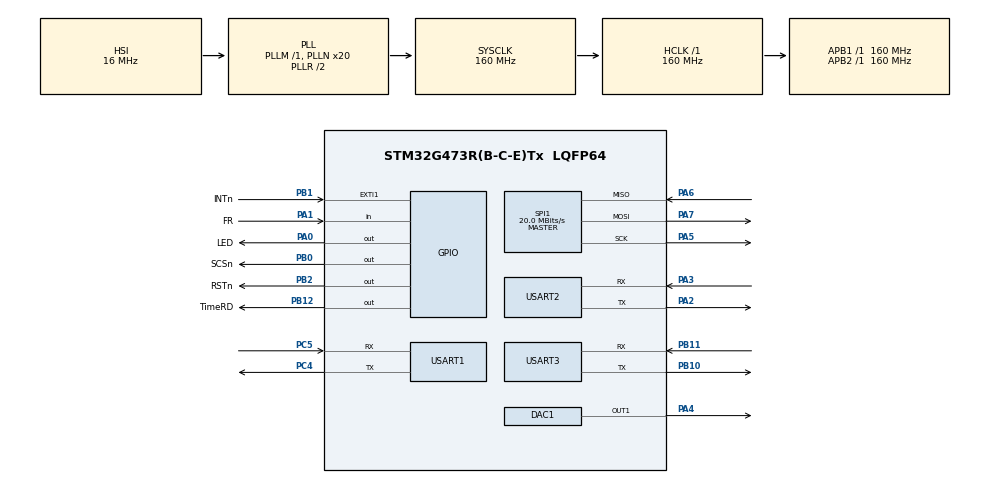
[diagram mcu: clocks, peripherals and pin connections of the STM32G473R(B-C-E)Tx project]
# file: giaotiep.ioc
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DAC1.DAC_Trigger_OUT1-DAC_OUT1=DAC_TRIGGER_T2_TRGO
Dma.DAC1_CH1.0.Direction=DMA_MEMORY_TO_PERIPH
Dma.DAC1_CH1.0.EventEnable=DISABLE
Dma.DAC1_CH1.0.Instance=DMA1_Channel1
Dma.DAC1_CH1.0.MemDataAlignment=DMA_MDATAALIGN_WORD
Dma.DAC1_CH1.0.MemInc=DMA_MINC_ENABLE
Dma.DAC1_CH1.0.Mode=DMA_CIRCULAR
Dma.DAC1_CH1.0.PeriphDataAlignment=DMA_PDATAALIGN_WORD
Dma.DAC1_CH1.0.PeriphInc=DMA_PINC_DISABLE
Dma.DAC1_CH1.0.Polarity=HAL_DMAMUX_REQ_GEN_RISING
Dma.DAC1_CH1.0.Priority=DMA_PRIORITY_HIGH
Dma.DAC1_CH1.0.RequestNumber=1
Dma.DAC1_CH1.0.SignalID=NONE
Dma.DAC1_CH1.0.SyncEnable=DISABLE
Dma.DAC1_CH1.0.SyncPolarity=HAL_DMAMUX_SYNC_NO_EVENT
Dma.DAC1_CH1.0.SyncRequestNumber=1
Dma.DAC1_CH1.0.SyncSignalID=NONE
Dma.Request0=DAC1_CH1
Mcu.Family=STM32G4
Mcu.Name=STM32G473R(B-C-E)Tx
Mcu.Package=LQFP64
NVIC.DMA1_Channel1_IRQn=true\:0\:0\:false\:false\:true\:false\:true\:true
NVIC.EXTI1_IRQn=true\:0\:0\:false\:false\:true\:true\:true\:true
NVIC.PriorityGroup=NVIC_PRIORITYGROUP_4
NVIC.TIM1_UP_TIM16_IRQn=true\:0\:0\:false\:false\:true\:true\:true\:true
NVIC.TIM20_UP_IRQn=true\:0\:0\:false\:false\:true\:true\:true\:true
NVIC.TIM3_IRQn=true\:0\:0\:false\:false\:true\:true\:true\:true
NVIC.USART1_IRQn=true\:0\:0\:false\:false\:true\:true\:true\:true
PA0.GPIO_Label=LED
PA0.Signal=GPIO_Output
PA1.GPIO_Label=FR
PA1.Signal=GPIO_Input
PA13.Mode=Serial_Wire
PA13.Signal=SYS_JTMS-SWDIO
PA14.Mode=Serial_Wire
PA14.Signal=SYS_JTCK-SWCLK
PA2.Mode=Asynchronous
PA2.Signal=USART2_TX
PA3.Mode=Asynchronous
PA3.Signal=USART2_RX
PA4.Signal=COMP_DAC11_group
PA5.Mode=Full_Duplex_Master
PA5.Signal=SPI1_SCK
PA6.Mode=Full_Duplex_Master
PA6.Signal=SPI1_MISO
PA7.Mode=Full_Duplex_Master
PA7.Signal=SPI1_MOSI
PB0.GPIO_Label=SCSn
PB0.Signal=GPIO_Output
PB1.GPIO_Label=INTn
PB1.GPIO_ModeDefaultEXTI=GPIO_MODE_IT_FALLING
PB1.GPIO_PuPd=GPIO_PULLUP
PB1.Signal=GPXTI1
PB10.Mode=Asynchronous
PB10.Signal=USART3_TX
PB11.Mode=Asynchronous
PB11.Signal=USART3_RX
PB12.GPIO_Label=TimeRD
PB12.Signal=GPIO_Output
PB2.GPIO_Label=RSTn
PB2.Signal=GPIO_Output
PC4.Mode=Asynchronous
PC4.Signal=USART1_TX
PC5.Mode=Asynchronous
PC5.Signal=USART1_RX
PF0-OSC_IN.Mode=HSE-External-Oscillator
PF0-OSC_IN.Signal=RCC_OSC_IN
PF1-OSC_OUT.Mode=HSE-External-Oscillator
PF1-OSC_OUT.Signal=RCC_OSC_OUT
ProjectManager.HeapSize=0x200
ProjectManager.StackSize=0x400
ProjectManager.TargetToolchain=MDK-ARM V5
RCC.ADC12Freq_Value=160000000
RCC.ADC345Freq_Value=160000000
RCC.AHBFreq_Value=160000000
RCC.APB1Freq_Value=160000000
RCC.APB1TimFreq_Value=160000000
RCC.APB2Freq_Value=160000000
RCC.APB2TimFreq_Value=160000000
RCC.CortexFreq_Value=160000000
RCC.EXTERNAL_CLOCK_VALUE=12288000
RCC.HCLKFreq_Value=160000000
RCC.HSE_VALUE=8000000
RCC.HSI48_VALUE=48000000
RCC.HSI_VALUE=16000000
RCC.LSE_VALUE=32768
RCC.PLLN=20
RCC.SYSCLKFreq_VALUE=160000000
RCC.SYSCLKSource=RCC_SYSCLKSOURCE_PLLCLK
RCC.USBFreq_Value=160000000
RCC.VCOOutputFreq_Value=320000000
SH.COMP_DAC11_group.0=DAC1_OUT1,DAC_OUT1
SPI1.BaudRatePrescaler=SPI_BAUDRATEPRESCALER_8
SPI1.CLKPhase=SPI_PHASE_2EDGE
SPI1.CLKPolarity=SPI_POLARITY_HIGH
SPI1.CRCCalculation=SPI_CRCCALCULATION_DISABLE
SPI1.CalculateBaudRate=20.0 MBits/s
SPI1.DataSize=SPI_DATASIZE_8BIT
SPI1.Direction=SPI_DIRECTION_2LINES
SPI1.Mode=SPI_MODE_MASTER
SPI1.VirtualType=VM_MASTER
TIM1.AutoReloadPreload=TIM_AUTORELOAD_PRELOAD_ENABLE
TIM1.PeriodNoDither=999
TIM1.Prescaler=79
TIM2.ClockDivision=TIM_CLOCKDIVISION_DIV1
TIM2.PeriodNoDither=1249
TIM2.TIM_MasterOutputTrigger=TIM_TRGO_UPDATE
TIM20.AutoReloadPreload=TIM_AUTORELOAD_PRELOAD_ENABLE
TIM20.PeriodNoDither=999
TIM20.Prescaler=79
TIM3.AutoReloadPreload=TIM_AUTORELOAD_PRELOAD_ENABLE
TIM3.PeriodNoDither=1000-1
TIM3.Prescaler=80-1
TIM3.TIM_MasterOutputTrigger=TIM_TRGO_RESET
USART1.VirtualMode-Asynchronous=VM_ASYNC
USART1.WordLength=WORDLENGTH_8B
USART2.VirtualMode-Asynchronous=VM_ASYNC
USART2.WordLength=WORDLENGTH_8B
USART3.VirtualMode-Asynchronous=VM_ASYNC
USART3.WordLength=WORDLENGTH_8B
VP_SYS_VS_DBSignals.Mode=DisableDeadBatterySignals
VP_TIM1_VS_ClockSourceINT.Mode=Internal
VP_TIM20_VS_ClockSourceINT.Mode=Internal
VP_TIM2_VS_ClockSourceINT.Mode=Internal
VP_TIM3_VS_ClockSourceINT.Mode=Internal
board=custom

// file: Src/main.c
/* USER CODE BEGIN Header */
/**
  ******************************************************************************
  * @file           : main.c
  * @brief          : Main program body
  ******************************************************************************
  * @attention
  *
  * <h2><center>&copy; Copyright (c) 2020 STMicroelectronics.
  * All rights reserved.</center></h2>
  *
  * This software component is licensed by ST under BSD 3-Clause license,
  * the "License"; You may not use this file except in compliance with the
  * License. You may obtain a copy of the License at:
  *                        opensource.org/licenses/BSD-3-Clause
  *
  ******************************************************************************
  */
/* USER CODE END Header */
#include "main.h"

/* USER CODE BEGIN Includes */
#include "stdio.h"
#include "wizchip_conf.h"
#include "irigb.h"
#include "storevalue.h"
#include <string.h>
/* USER CODE END Includes */

/* USER CODE BEGIN PM */
uint32_t	_loop1=0;
#define NS  128
uint32_t Wave_LUT[NS] = {
    2048, 2149, 2250, 2350, 2450, 2549, 2646, 2742, 2837, 2929, 3020, 3108, 3193, 3275, 3355,
    3431, 3504, 3574, 3639, 3701, 3759, 3812, 3861, 3906, 3946, 3982, 4013, 4039, 4060, 4076,
    4087, 4094, 4095, 4091, 4082, 4069, 4050, 4026, 3998, 3965, 3927, 3884, 3837, 3786, 3730,
    3671, 3607, 3539, 3468, 3394, 3316, 3235, 3151, 3064, 2975, 2883, 2790, 2695, 2598, 2500,
    2400, 2300, 2199, 2098, 1997, 1896, 1795, 1695, 1595, 1497, 1400, 1305, 1212, 1120, 1031,
    944, 860, 779, 701, 627, 556, 488, 424, 365, 309, 258, 211, 168, 130, 97,
    69, 45, 26, 13, 4, 0, 1, 8, 19, 35, 56, 82, 113, 149, 189,
    234, 283, 336, 394, 456, 521, 591, 664, 740, 820, 902, 987, 1075, 1166, 1258,
    1353, 1449, 1546, 1645, 1745, 1845, 1946, 2047
};

/* USER CODE END PM */

 DAC_HandleTypeDef hdac1;
DMA_HandleTypeDef hdma_dac1_ch1;

SPI_HandleTypeDef hspi1;

TIM_HandleTypeDef htim1;
TIM_HandleTypeDef htim2;
TIM_HandleTypeDef htim3;
TIM_HandleTypeDef htim20;

UART_HandleTypeDef huart1;
UART_HandleTypeDef huart2;
UART_HandleTypeDef huart3;

/* USER CODE BEGIN PV */
uint8_t u1Timeout=0;
uint32_t tim20ct=0;
/* Size of Reception buffer */
#define RXBUFFERSIZE                      10
/* Buffer used for reception */
uint8_t aRxBuffer[RXBUFFERSIZE];

wiz_NetInfo gWIZNETINFO = { .mac = {0x01, 0x08, 0xDC,0x4F, 0xEB, 0x6E},
                            .ip = {192, 168, 22, 163},
                            .sn = {255,255,255,1},
                            .gw = {192, 168, 22, 252},
                            .dns = {8,8,8,8},
                            .dhcp = NETINFO_STATIC };
/* USER CODE END PV */

void SystemClock_Config(void);
static void MX_GPIO_Init(void);
static void MX_DMA_Init(void);
static void MX_DAC1_Init(void);
static void MX_SPI1_Init(void);
static void MX_TIM1_Init(void);
static void MX_USART1_UART_Init(void);
static void MX_USART2_UART_Init(void);
static void MX_USART3_UART_Init(void);
static void MX_TIM2_Init(void);
static void MX_TIM20_Init(void);
static void MX_TIM3_Init(void);
/* USER CODE BEGIN PFP */
static void  wizchip_select(void)
{
	//GPIO_ResetBits(W5500_CS_GPIO_PORT, W5500_CS_PIN);
	HAL_GPIO_WritePin(SCSn_GPIO_Port, SCSn_Pin, GPIO_PIN_RESET);
}
static void  wizchip_deselect(void)
{
	//GPIO_SetBits(W5500_CS_GPIO_PORT, W5500_CS_PIN);
	uint8_t temp=0xff;
	HAL_GPIO_WritePin(SCSn_GPIO_Port, SCSn_Pin, GPIO_PIN_SET);
	HAL_SPI_Transmit(&hspi1,&temp,1,100);
	//stm32_spi_rw(0xFF);
}
static uint8_t wizchip_read(void)
{
	uint8_t temp;
	//while (  SPI_I2S_GetFlagStatus(SPI2 , SPI_I2S_FLAG_TXE) == RESET );
	//SPI_I2S_SendData(SPI2 , 0xff);     // Dummy write to generate clock
	//while (  SPI_I2S_GetFlagStatus(SPI2 , SPI_I2S_FLAG_RXNE) == RESET );
	//return (unsigned char)SPI_I2S_ReceiveData(SPI2);

	HAL_SPI_Receive(&hspi1,&temp,1,100);
	return temp;
}
static void  wizchip_write(uint8_t wb)
{
	//while (  SPI_I2S_GetFlagStatus(SPI2 , SPI_I2S_FLAG_TXE) == RESET );  // sending data Wait
	//SPI_I2S_SendData(SPI2 , wb);
	//while (  SPI_I2S_GetFlagStatus(SPI2 , SPI_I2S_FLAG_RXNE) == RESET ); // Wait for data
	//wb = SPI_I2S_ReceiveData(SPI2);        // Dummy read to generate clock
	HAL_SPI_Transmit(&hspi1,&wb,1,100);
}
static void wizchip_readburst(uint8_t* pBuf, uint16_t len)
{
	//stm32_wizchip_dma_transfer(1, pBuf, len);  //FALSE(0) for buff->SPI, TRUE(1) for SPI->buff
	HAL_SPI_Receive(&hspi1,pBuf,len,100);
}

static void  wizchip_writeburst(uint8_t* pBuf, uint16_t len)
{
	//stm32_wizchip_dma_transfer(0, pBuf, len);  //FALSE(0) for buff->SPI, TRUE(1) for SPI->buff
	HAL_SPI_Transmit(&hspi1,pBuf,len,100);
}

void Display_Net_Conf()
{
	uint8_t tmpstr[6] = {0,};
	wiz_NetInfo gWIZNETINFO;

	ctlnetwork(CN_GET_NETINFO, (void*) &gWIZNETINFO);
	ctlwizchip(CW_GET_ID,(void*)tmpstr);

	// Display Network Information
	if(gWIZNETINFO.dhcp == NETINFO_DHCP) printf("\r\n===== %s NET CONF : DHCP =====\r\n",(char*)tmpstr);
		else printf("\r\n===== %s NET CONF : Static =====\r\n",(char*)tmpstr);

	printf("\r\nMAC: %02X:%02X:%02X:%02X:%02X:%02X\r\n", gWIZNETINFO.mac[0], gWIZNETINFO.mac[1], gWIZNETINFO.mac[2], gWIZNETINFO.mac[3], gWIZNETINFO.mac[4], gWIZNETINFO.mac[5]);
	printf("IP: %d.%d.%d.%d\r\n", gWIZNETINFO.ip[0], gWIZNETINFO.ip[1], gWIZNETINFO.ip[2], gWIZNETINFO.ip[3]);
	printf("GW: %d.%d.%d.%d\r\n", gWIZNETINFO.gw[0], gWIZNETINFO.gw[1], gWIZNETINFO.gw[2], gWIZNETINFO.gw[3]);
	printf("SN: %d.%d.%d.%d\r\n", gWIZNETINFO.sn[0], gWIZNETINFO.sn[1], gWIZNETINFO.sn[2], gWIZNETINFO.sn[3]);
	printf("DNS: %d.%d.%d.%d\r\n", gWIZNETINFO.dns[0], gWIZNETINFO.dns[1], gWIZNETINFO.dns[2], gWIZNETINFO.dns[3]);

	//printf("\r\n=== DNS Client Example ===============\r\n");
  //printf("> DNS 1st : %d.%d.%d.%d\r\n", gWIZNETINFO.dns[0], gWIZNETINFO.dns[1], gWIZNETINFO.dns[2], gWIZNETINFO.dns[3]);
  //printf("> DNS 2nd : %d.%d.%d.%d\r\n", DNS_2nd[0], DNS_2nd[1], DNS_2nd[2], DNS_2nd[3]);
  //printf("======================================\r\n");
   //printf("> Example Domain Name : %s\r\n", Domain_name);
}

void Net_Conf(wiz_NetInfo netinfo)
{
	/*
	wiz_NetInfo gWIZNETINFO = {
		{ 0x00, 0x08, 0xDC, 0x44, 0x55, 0x66 },				// Mac address
		{ 192, 168, 1, 91 },								// IP address
		{ 255, 255, 255, 0},								// Subnet mask
		{ 192, 168, 1, 1},									// Gateway
		{ 8, 8, 8, 8},										// DNS Server
	};
	*/
	ctlnetwork(CN_SET_NETINFO, (void*) &netinfo);

	Display_Net_Conf();
}
void w5500_lib_init(void){

		uint8_t tmp;
		intr_kind temp;
		uint8_t memsize[2][8] = {{2,2,2,2,2,2,2,2},{2,2,2,2,2,2,2,2}};

		//printf("w5500_lib_init...1");
		//GPIO_ResetBits(W5500_RST_GPIO, W5500_RST);
		HAL_GPIO_WritePin(RSTn_GPIO_Port, RSTn_Pin, GPIO_PIN_RESET);
		HAL_Delay(100);

		//////////
   // TODO //
   ////////////////////////////////////////////////////////////////////////////////////////////////////
   // First of all, Should register SPI callback functions implemented by user for accessing WIZCHIP //
   ////////////////////////////////////////////////////////////////////////////////////////////////////

		/* Critical section callback - No use in this example */
		//reg_wizchip_cris_cbfunc(0, 0);

    /* Chip selection call back */
		reg_wizchip_cs_cbfunc(wizchip_select, wizchip_deselect);
		/* SPI Read & Write callback function */
    reg_wizchip_spi_cbfunc(wizchip_read, wizchip_write);
		reg_wizchip_spiburst_cbfunc(wizchip_readburst, wizchip_writeburst);
		//GPIO_SetBits(W5500_RST_GPIO, W5500_RST);//RST High to run
		HAL_GPIO_WritePin(RSTn_GPIO_Port, RSTn_Pin, GPIO_PIN_SET);
		HAL_Delay(100);
		//printf("...2");
    ////////////////////////////////////////////////////////////////////////
		/* WIZCHIP SOCKET Buffer initialize */
		//Initializes to WIZCHIP with SOCKET buffer size 2 or 1 dimension array typed uint8_t
    if(ctlwizchip(CW_INIT_WIZCHIP,(void*)memsize) == -1)
    {
       printf("WIZCHIP Initialized fail.\r\n");
       //while(1);
    }

		//printf("...get PHY Link status");
		/* PHY link status check */

		do
    {
       if(ctlwizchip(CW_GET_PHYLINK, (void*)&tmp) == -1)
          ;//printf("Unknown PHY Link stauts.\r\n");
    }while(tmp == PHY_LINK_OFF);
		//printf("...4");
		//Cau hinh ngat tren S0
		temp = IK_SOCK_0;
		if(ctlwizchip(CW_SET_INTRMASK, &temp) == WZN_ERR)
		{
			printf("Cannot set imr...\r\n");
		}
		//printf("...all ok\r\n");
		Net_Conf(gWIZNETINFO);

}

static uint32_t GetPage(uint32_t Address);
static uint32_t GetBank(uint32_t Address);
static void storeValue(void);
static void loadValue(void);
/* USER CODE END PFP */

int main(void)
{
  /* USER CODE BEGIN 1 */
uint8_t u2data[100];

  /* USER CODE END 1 */

  /* MCU Configuration--------------------------------------------------------*/

  /* Reset of all peripherals, Initializes the Flash interface and the Systick. */
  HAL_Init();

  /* Configure the system clock */
  SystemClock_Config();

  /* Initialize all configured peripherals */
  MX_GPIO_Init();
  MX_DMA_Init();
  MX_DAC1_Init();
  MX_SPI1_Init();
  MX_TIM1_Init();
  MX_USART1_UART_Init();
  MX_USART2_UART_Init();
  MX_USART3_UART_Init();
  MX_TIM2_Init();
  MX_TIM20_Init();
  MX_TIM3_Init();
  /* USER CODE BEGIN 2 */

	HAL_GPIO_WritePin(GPIOA, LED_Pin, GPIO_PIN_SET);
	//HAL_GPIO_WritePin(RD485_GPIO_Port, RD485_Pin, GPIO_PIN_SET);
	HAL_Delay(100);

	// Toc do 160MHz, TIM2 1250-1 = 1249, IRIG-B freq = 1Khz !!!!

	printf("This code gen by STMcube STM32G473RBT@160MHz\r\n");
	//HAL_UART_Transmit(&huart1, (uint8_t *)&ch, 1, 100);
	HAL_UART_Transmit(&huart2, (uint8_t *)"UART2 TX ok\r\n", 13, 100);

	w5500_lib_init();
	HAL_DAC_Start(&hdac1, DAC_CHANNEL_1);
	HAL_DAC_Start_DMA(&hdac1, DAC_CHANNEL_1, (uint32_t*)_Bit0, 1280, DAC_ALIGN_12B_R);
	//hdma_dac1_ch1.Instance->CMAR = (uint32_t)_Bit0;
  HAL_TIM_Base_Start(&htim2);
	HAL_TIM_Base_Start_IT(&htim3);

	//HAL_DAC_Start(&hdac1, DAC_CHANNEL_1);
	//HAL_DAC_SetValue(&hdac1, DAC_CHANNEL_1,DAC_ALIGN_12B_R,4000);
	printf("Run\r\n");

	storeValue();
	loadValue();

	//HAL_GPIO_WritePin(RD485_GPIO_Port, RD485_Pin, GPIO_PIN_RESET);
	//MX_IWDG_Init();
  /* USER CODE END 2 */

  /* Infinite loop */
  /* USER CODE BEGIN WHILE */
	  /*##-2- Put UART peripheral in reception process ###########################*/
  /* Any data received will be stored in "aRxBuffer" buffer : the number max of
     data received is 10
		 Du lieu nhan dc se tu dong luu vao aRxBuffer
		 */
  if (HAL_UART_Receive_IT(&huart1, (uint8_t *)aRxBuffer, RXBUFFERSIZE) != HAL_OK)
  {
    /* Transfer error in reception process */
    Error_Handler();
  }

	//htim20.Instance->CNT =0;
  while (1)
  {
    //HAL_IWDG_Refresh(&hiwdg);
		//HAL_UART_Receive(&huart2, u2data,20,100);
		//printf("u2data:%s\r\n",u2data);
		//HAL_Delay(100);
		//HAL_GPIO_WritePin(GPIOA, GPIO_PIN_0, 0);
		//HAL_DAC_SetValue(&hdac1, DAC_CHANNEL_1,DAC_ALIGN_12B_R,4000);
    //HAL_Delay(500);
    //HAL_GPIO_WritePin(GPIOA, GPIO_PIN_0, 1);
		//HAL_DAC_SetValue(&hdac1, DAC_CHANNEL_1,DAC_ALIGN_12B_R,400);
    //HAL_Delay(450);

		//tim20ct= __HAL_TIM_GET_COUNTER(&htim3);

		//printf("tim20ct:%d\r\n",tim20ct);

		if(tim20ct > 1000) {
			tim20ct = 0;
			HAL_GPIO_WritePin(GPIOA, GPIO_PIN_0, 0);

			//printf("1s\r\n");
			HAL_Delay(50);
			HAL_GPIO_WritePin(GPIOA, GPIO_PIN_0, 1);

			HAL_Delay(50);
		}
		if(u1Timeout == 1)
			{
				u1Timeout = 0;
				printf("aRxBuffer %s; \r\n",aRxBuffer);
				huart1.pRxBuffPtr = (uint8_t *)aRxBuffer;
				huart1.RxXferCount = RXBUFFERSIZE;
				memset(aRxBuffer,0,RXBUFFERSIZE);
			}
    /* USER CODE END WHILE */

  }
}

void SystemClock_Config(void)
{
  RCC_OscInitTypeDef RCC_OscInitStruct = {0};
  RCC_ClkInitTypeDef RCC_ClkInitStruct = {0};

  /** Configure the main internal regulator output voltage
  */
  HAL_PWREx_ControlVoltageScaling(PWR_REGULATOR_VOLTAGE_SCALE1_BOOST);

  /** Initializes the RCC Oscillators according to the specified parameters
  * in the RCC_OscInitTypeDef structure.
  */
  RCC_OscInitStruct.OscillatorType = RCC_OSCILLATORTYPE_HSI;
  RCC_OscInitStruct.HSIState = RCC_HSI_ON;
  RCC_OscInitStruct.HSICalibrationValue = RCC_HSICALIBRATION_DEFAULT;
  RCC_OscInitStruct.PLL.PLLState = RCC_PLL_ON;
  RCC_OscInitStruct.PLL.PLLSource = RCC_PLLSOURCE_HSI;
  RCC_OscInitStruct.PLL.PLLM = RCC_PLLM_DIV1;
  RCC_OscInitStruct.PLL.PLLN = 20;
  RCC_OscInitStruct.PLL.PLLP = RCC_PLLP_DIV2;
  RCC_OscInitStruct.PLL.PLLQ = RCC_PLLQ_DIV2;
  RCC_OscInitStruct.PLL.PLLR = RCC_PLLR_DIV2;
  if (HAL_RCC_OscConfig(&RCC_OscInitStruct) != HAL_OK)
  {
    Error_Handler();
  }

  /** Initializes the CPU, AHB and APB buses clocks
  */
  RCC_ClkInitStruct.ClockType = RCC_CLOCKTYPE_HCLK|RCC_CLOCKTYPE_SYSCLK
                              |RCC_CLOCKTYPE_PCLK1|RCC_CLOCKTYPE_PCLK2;
  RCC_ClkInitStruct.SYSCLKSource = RCC_SYSCLKSOURCE_PLLCLK;
  RCC_ClkInitStruct.AHBCLKDivider = RCC_SYSCLK_DIV1;
  RCC_ClkInitStruct.APB1CLKDivider = RCC_HCLK_DIV1;
  RCC_ClkInitStruct.APB2CLKDivider = RCC_HCLK_DIV1;

  if (HAL_RCC_ClockConfig(&RCC_ClkInitStruct, FLASH_LATENCY_4) != HAL_OK)
  {
    Error_Handler();
  }
}

static void MX_DAC1_Init(void)
{

  DAC_ChannelConfTypeDef sConfig = {0};

  /** DAC Initialization
  */
  hdac1.Instance = DAC1;
  if (HAL_DAC_Init(&hdac1) != HAL_OK)
  {
    Error_Handler();
  }

  /** DAC channel OUT1 config
  */
  sConfig.DAC_HighFrequency = DAC_HIGH_FREQUENCY_INTERFACE_MODE_AUTOMATIC;
  sConfig.DAC_DMADoubleDataMode = DISABLE;
  sConfig.DAC_SignedFormat = DISABLE;
  sConfig.DAC_SampleAndHold = DAC_SAMPLEANDHOLD_DISABLE;
  sConfig.DAC_Trigger = DAC_TRIGGER_T2_TRGO;
  sConfig.DAC_Trigger2 = DAC_TRIGGER_NONE;
  sConfig.DAC_OutputBuffer = DAC_OUTPUTBUFFER_ENABLE;
  sConfig.DAC_ConnectOnChipPeripheral = DAC_CHIPCONNECT_EXTERNAL;
  sConfig.DAC_UserTrimming = DAC_TRIMMING_FACTORY;
  if (HAL_DAC_ConfigChannel(&hdac1, &sConfig, DAC_CHANNEL_1) != HAL_OK)
  {
    Error_Handler();
  }

}

static void MX_SPI1_Init(void)
{

  /* SPI1 parameter configuration*/
  hspi1.Instance = SPI1;
  hspi1.Init.Mode = SPI_MODE_MASTER;
  hspi1.Init.Direction = SPI_DIRECTION_2LINES;
  hspi1.Init.DataSize = SPI_DATASIZE_8BIT;
  hspi1.Init.CLKPolarity = SPI_POLARITY_HIGH;
  hspi1.Init.CLKPhase = SPI_PHASE_2EDGE;
  hspi1.Init.NSS = SPI_NSS_SOFT;
  hspi1.Init.BaudRatePrescaler = SPI_BAUDRATEPRESCALER_8;
  hspi1.Init.FirstBit = SPI_FIRSTBIT_MSB;
  hspi1.Init.TIMode = SPI_TIMODE_DISABLE;
  hspi1.Init.CRCCalculation = SPI_CRCCALCULATION_DISABLE;
  hspi1.Init.CRCPolynomial = 7;
  hspi1.Init.CRCLength = SPI_CRC_LENGTH_DATASIZE;
  hspi1.Init.NSSPMode = SPI_NSS_PULSE_DISABLE;
  if (HAL_SPI_Init(&hspi1) != HAL_OK)
  {
    Error_Handler();
  }

}

static void MX_TIM1_Init(void)
{

  TIM_ClockConfigTypeDef sClockSourceConfig = {0};
  TIM_MasterConfigTypeDef sMasterConfig = {0};

  htim1.Instance = TIM1;
  htim1.Init.Prescaler = 79;
  htim1.Init.CounterMode = TIM_COUNTERMODE_UP;
  htim1.Init.Period = 999;
  htim1.Init.ClockDivision = TIM_CLOCKDIVISION_DIV1;
  htim1.Init.RepetitionCounter = 0;
  htim1.Init.AutoReloadPreload = TIM_AUTORELOAD_PRELOAD_ENABLE;
  if (HAL_TIM_Base_Init(&htim1) != HAL_OK)
  {
    Error_Handler();
  }
  sClockSourceConfig.ClockSource = TIM_CLOCKSOURCE_INTERNAL;
  if (HAL_TIM_ConfigClockSource(&htim1, &sClockSourceConfig) != HAL_OK)
  {
    Error_Handler();
  }
  sMasterConfig.MasterOutputTrigger = TIM_TRGO_RESET;
  sMasterConfig.MasterOutputTrigger2 = TIM_TRGO2_RESET;
  sMasterConfig.MasterSlaveMode = TIM_MASTERSLAVEMODE_DISABLE;
  if (HAL_TIMEx_MasterConfigSynchronization(&htim1, &sMasterConfig) != HAL_OK)
  {
    Error_Handler();
  }

}

static void MX_TIM2_Init(void)
{

  TIM_ClockConfigTypeDef sClockSourceConfig = {0};
  TIM_MasterConfigTypeDef sMasterConfig = {0};

  htim2.Instance = TIM2;
  htim2.Init.Prescaler = 0;
  htim2.Init.CounterMode = TIM_COUNTERMODE_UP;
  htim2.Init.Period = 1249;
  htim2.Init.ClockDivision = TIM_CLOCKDIVISION_DIV1;
  htim2.Init.AutoReloadPreload = TIM_AUTORELOAD_PRELOAD_DISABLE;
  if (HAL_TIM_Base_Init(&htim2) != HAL_OK)
  {
    Error_Handler();
  }
  sClockSourceConfig.ClockSource = TIM_CLOCKSOURCE_INTERNAL;
  if (HAL_TIM_ConfigClockSource(&htim2, &sClockSourceConfig) != HAL_OK)
  {
    Error_Handler();
  }
  sMasterConfig.MasterOutputTrigger = TIM_TRGO_UPDATE;
  sMasterConfig.MasterSlaveMode = TIM_MASTERSLAVEMODE_DISABLE;
  if (HAL_TIMEx_MasterConfigSynchronization(&htim2, &sMasterConfig) != HAL_OK)
  {
    Error_Handler();
  }

}

static void MX_TIM3_Init(void)
{

  TIM_ClockConfigTypeDef sClockSourceConfig = {0};
  TIM_MasterConfigTypeDef sMasterConfig = {0};

  htim3.Instance = TIM3;
  htim3.Init.Prescaler = 80-1;
  htim3.Init.CounterMode = TIM_COUNTERMODE_UP;
  htim3.Init.Period = 999;
  htim3.Init.ClockDivision = TIM_CLOCKDIVISION_DIV1;
  htim3.Init.AutoReloadPreload = TIM_AUTORELOAD_PRELOAD_ENABLE;
  if (HAL_TIM_Base_Init(&htim3) != HAL_OK)
  {
    Error_Handler();
  }
  sClockSourceConfig.ClockSource = TIM_CLOCKSOURCE_INTERNAL;
  if (HAL_TIM_ConfigClockSource(&htim3, &sClockSourceConfig) != HAL_OK)
  {
    Error_Handler();
  }
  sMasterConfig.MasterOutputTrigger = TIM_TRGO_RESET;
  sMasterConfig.MasterSlaveMode = TIM_MASTERSLAVEMODE_DISABLE;
  if (HAL_TIMEx_MasterConfigSynchronization(&htim3, &sMasterConfig) != HAL_OK)
  {
    Error_Handler();
  }

}

static void MX_TIM20_Init(void)
{

  TIM_ClockConfigTypeDef sClockSourceConfig = {0};
  TIM_MasterConfigTypeDef sMasterConfig = {0};

  htim20.Instance = TIM20;
  htim20.Init.Prescaler = 79;
  htim20.Init.CounterMode = TIM_COUNTERMODE_UP;
  htim20.Init.Period = 999;
  htim20.Init.ClockDivision = TIM_CLOCKDIVISION_DIV1;
  htim20.Init.RepetitionCounter = 0;
  htim20.Init.AutoReloadPreload = TIM_AUTORELOAD_PRELOAD_ENABLE;
  if (HAL_TIM_Base_Init(&htim20) != HAL_OK)
  {
    Error_Handler();
  }
  sClockSourceConfig.ClockSource = TIM_CLOCKSOURCE_INTERNAL;
  if (HAL_TIM_ConfigClockSource(&htim20, &sClockSourceConfig) != HAL_OK)
  {
    Error_Handler();
  }
  sMasterConfig.MasterOutputTrigger = TIM_TRGO_RESET;
  sMasterConfig.MasterOutputTrigger2 = TIM_TRGO2_RESET;
  sMasterConfig.MasterSlaveMode = TIM_MASTERSLAVEMODE_DISABLE;
  if (HAL_TIMEx_MasterConfigSynchronization(&htim20, &sMasterConfig) != HAL_OK)
  {
    Error_Handler();
  }

}

static void MX_USART1_UART_Init(void)
{

  huart1.Instance = USART1;
  huart1.Init.BaudRate = 115200;
  huart1.Init.WordLength = UART_WORDLENGTH_8B;
  huart1.Init.StopBits = UART_STOPBITS_1;
  huart1.Init.Parity = UART_PARITY_NONE;
  huart1.Init.Mode = UART_MODE_TX_RX;
  huart1.Init.HwFlowCtl = UART_HWCONTROL_NONE;
  huart1.Init.OverSampling = UART_OVERSAMPLING_16;
  huart1.Init.OneBitSampling = UART_ONE_BIT_SAMPLE_DISABLE;
  huart1.Init.ClockPrescaler = UART_PRESCALER_DIV1;
  huart1.AdvancedInit.AdvFeatureInit = UART_ADVFEATURE_NO_INIT;
  if (HAL_UART_Init(&huart1) != HAL_OK)
  {
    Error_Handler();
  }
  if (HAL_UARTEx_SetTxFifoThreshold(&huart1, UART_TXFIFO_THRESHOLD_1_8) != HAL_OK)
  {
    Error_Handler();
  }
  if (HAL_UARTEx_SetRxFifoThreshold(&huart1, UART_RXFIFO_THRESHOLD_1_8) != HAL_OK)
  {
    Error_Handler();
  }
  if (HAL_UARTEx_DisableFifoMode(&huart1) != HAL_OK)
  {
    Error_Handler();
  }

}

static void MX_USART2_UART_Init(void)
{

  huart2.Instance = USART2;
  huart2.Init.BaudRate = 115200;
  huart2.Init.WordLength = UART_WORDLENGTH_8B;
  huart2.Init.StopBits = UART_STOPBITS_1;
  huart2.Init.Parity = UART_PARITY_NONE;
  huart2.Init.Mode = UART_MODE_TX_RX;
  huart2.Init.HwFlowCtl = UART_HWCONTROL_NONE;
  huart2.Init.OverSampling = UART_OVERSAMPLING_16;
  huart2.Init.OneBitSampling = UART_ONE_BIT_SAMPLE_DISABLE;
  huart2.Init.ClockPrescaler = UART_PRESCALER_DIV1;
  huart2.AdvancedInit.AdvFeatureInit = UART_ADVFEATURE_NO_INIT;
  if (HAL_UART_Init(&huart2) != HAL_OK)
  {
    Error_Handler();
  }
  if (HAL_UARTEx_SetTxFifoThreshold(&huart2, UART_TXFIFO_THRESHOLD_1_8) != HAL_OK)
  {
    Error_Handler();
  }
  if (HAL_UARTEx_SetRxFifoThreshold(&huart2, UART_RXFIFO_THRESHOLD_1_8) != HAL_OK)
  {
    Error_Handler();
  }
  if (HAL_UARTEx_DisableFifoMode(&huart2) != HAL_OK)
  {
    Error_Handler();
  }

}

static void MX_USART3_UART_Init(void)
{

  huart3.Instance = USART3;
  huart3.Init.BaudRate = 115200;
  huart3.Init.WordLength = UART_WORDLENGTH_8B;
  huart3.Init.StopBits = UART_STOPBITS_1;
  huart3.Init.Parity = UART_PARITY_NONE;
  huart3.Init.Mode = UART_MODE_TX_RX;
  huart3.Init.HwFlowCtl = UART_HWCONTROL_NONE;
  huart3.Init.OverSampling = UART_OVERSAMPLING_16;
  huart3.Init.OneBitSampling = UART_ONE_BIT_SAMPLE_DISABLE;
  huart3.Init.ClockPrescaler = UART_PRESCALER_DIV1;
  huart3.AdvancedInit.AdvFeatureInit = UART_ADVFEATURE_NO_INIT;
  if (HAL_UART_Init(&huart3) != HAL_OK)
  {
    Error_Handler();
  }
  if (HAL_UARTEx_SetTxFifoThreshold(&huart3, UART_TXFIFO_THRESHOLD_1_8) != HAL_OK)
  {
    Error_Handler();
  }
  if (HAL_UARTEx_SetRxFifoThreshold(&huart3, UART_RXFIFO_THRESHOLD_1_8) != HAL_OK)
  {
    Error_Handler();
  }
  if (HAL_UARTEx_DisableFifoMode(&huart3) != HAL_OK)
  {
    Error_Handler();
  }

}

static void MX_DMA_Init(void)
{

  /* DMA controller clock enable */
  __HAL_RCC_DMAMUX1_CLK_ENABLE();
  __HAL_RCC_DMA1_CLK_ENABLE();

  /* DMA interrupt init */
  /* DMA1_Channel1_IRQn interrupt configuration */
  HAL_NVIC_SetPriority(DMA1_Channel1_IRQn, 0, 0);
  HAL_NVIC_EnableIRQ(DMA1_Channel1_IRQn);

}

static void MX_GPIO_Init(void)
{
  GPIO_InitTypeDef GPIO_InitStruct = {0};

  /* GPIO Ports Clock Enable */
  __HAL_RCC_GPIOF_CLK_ENABLE();
  __HAL_RCC_GPIOA_CLK_ENABLE();
  __HAL_RCC_GPIOC_CLK_ENABLE();
  __HAL_RCC_GPIOB_CLK_ENABLE();

  /*Configure GPIO pin Output Level */
  HAL_GPIO_WritePin(LED_GPIO_Port, LED_Pin, GPIO_PIN_RESET);

  /*Configure GPIO pin Output Level */
  HAL_GPIO_WritePin(GPIOB, SCSn_Pin|RSTn_Pin|TimeRD_Pin, GPIO_PIN_RESET);

  /*Configure GPIO pin : LED_Pin */
  GPIO_InitStruct.Pin = LED_Pin;
  GPIO_InitStruct.Mode = GPIO_MODE_OUTPUT_PP;
  GPIO_InitStruct.Pull = GPIO_NOPULL;
  GPIO_InitStruct.Speed = GPIO_SPEED_FREQ_LOW;
  HAL_GPIO_Init(LED_GPIO_Port, &GPIO_InitStruct);

  /*Configure GPIO pin : FR_Pin */
  GPIO_InitStruct.Pin = FR_Pin;
  GPIO_InitStruct.Mode = GPIO_MODE_INPUT;
  GPIO_InitStruct.Pull = GPIO_NOPULL;
  HAL_GPIO_Init(FR_GPIO_Port, &GPIO_InitStruct);

  /*Configure GPIO pins : SCSn_Pin RSTn_Pin TimeRD_Pin */
  GPIO_InitStruct.Pin = SCSn_Pin|RSTn_Pin|TimeRD_Pin;
  GPIO_InitStruct.Mode = GPIO_MODE_OUTPUT_PP;
  GPIO_InitStruct.Pull = GPIO_NOPULL;
  GPIO_InitStruct.Speed = GPIO_SPEED_FREQ_LOW;
  HAL_GPIO_Init(GPIOB, &GPIO_InitStruct);

  /*Configure GPIO pin : INTn_Pin */
  GPIO_InitStruct.Pin = INTn_Pin;
  GPIO_InitStruct.Mode = GPIO_MODE_IT_FALLING;
  GPIO_InitStruct.Pull = GPIO_PULLUP;
  HAL_GPIO_Init(INTn_GPIO_Port, &GPIO_InitStruct);

  /* EXTI interrupt init*/
  HAL_NVIC_SetPriority(EXTI1_IRQn, 0, 0);
  HAL_NVIC_EnableIRQ(EXTI1_IRQn);

}

/* USER CODE BEGIN 4 */

#ifdef __GNUC__
  /* With GCC/RAISONANCE, small printf (option LD Linker->Libraries->Small printf
     set to 'Yes') calls __io_putchar() */
  #define PUTCHAR_PROTOTYPE int __io_putchar(int ch)
#else
  #define PUTCHAR_PROTOTYPE int fputc(int ch, FILE *f)
#endif /* __GNUC__ */

/**
  * @brief  Retargets the C library printf function to the USART.
  * @param  None
  * @retval None
  */
PUTCHAR_PROTOTYPE
{
	/* Place your implementation of fputc here */
	/* e.g. write a character to the USART */
	HAL_UART_Transmit(&huart1, (uint8_t *)&ch, 1, 100);
	//start loop1
	//_loop1 = _loop1_run;
	return ch;
}

/**
  * @brief  Rx Transfer completed callback
  * @param  UartHandle: UART handle
  * @note   This example shows a simple way to report end of IT Rx transfer, and
  *         you can add your own implementation.
  * @retval None
  */
void HAL_UART_RxCpltCallback(UART_HandleTypeDef *UartHandle)
{
  if (UartHandle->Instance == USART1)
		{

		}
		//printf("aRxBuffer %s; \r\n",aRxBuffer);
		//HAL_Delay(1000);
}

void HAL_DAC_ConvCpltCallbackCh1(DAC_HandleTypeDef *hdac)
{

	if(_loop1 == 0)
		{
			_loop1 = 1;
			//HAL_DAC_Start_DMA(&hdac1, DAC_CHANNEL_1, (uint32_t*)_Bit0, 1280, DAC_ALIGN_12B_R);
			hdma_dac1_ch1.Instance->CMAR = (uint32_t)_Bit0;
		}
	else
		{
			//HAL_DAC_Start_DMA(&hdac1, DAC_CHANNEL_1, (uint32_t*)_BitREF, 1280, DAC_ALIGN_12B_R);
			hdma_dac1_ch1.Instance->CMAR = (uint32_t)_BitREF;
			_loop1 = 0;
		}
};
//void HAL_DMA_RegisterCallback
static void loadValue(void)
{
	__IO uint32_t MemoryProgramStatus = 0;
	__IO uint32_t data32 = 0;
	uint32_t Address = 0;
	/* Check if the programmed data is OK
      MemoryProgramStatus = 0: data programmed correctly
      MemoryProgramStatus != 0: number of words not programmed correctly ******/

  MemoryProgramStatus = 0x0;

    data32 = *(__IO uint32_t *)FLASH_USER_START_ADDR;

    if (data32 != DATA_32)
    {
      MemoryProgramStatus++;
    }

	/*Check if there is an issue to program data*/
  if (MemoryProgramStatus == 0)
  {
    /* No error detected. Switch on LED1*/
    //BSP_LED_On(LED1);
		printf("Memory is ok\r\n");
  }
  else
  {
    /* Error detected. Switch on LED3*/
    //BSP_LED_On(LED3);
		printf("Error detected \r\n");
		return;
  }

	data32 = *(__IO uint32_t *)(FLASH_USER_START_ADDR+4);
	//printf("first data32 %x\r\n",data32);

	gWIZNETINFO.ip[3] = (uint8_t)data32;
	gWIZNETINFO.ip[2] = (uint8_t)(data32>>8);
	gWIZNETINFO.ip[1] = (uint8_t)(data32>>16);
	gWIZNETINFO.ip[0] = (uint8_t)(data32>>24);
	printf("Load IP: %d.%d.%d.%d\r\n",gWIZNETINFO.ip[0],gWIZNETINFO.ip[1],gWIZNETINFO.ip[2],gWIZNETINFO.ip[3]);

	data32 = *(__IO uint32_t *)(FLASH_USER_START_ADDR+8);
	printf("last data32 %x\r\n",data32);
		data32 = *(__IO uint32_t *)(FLASH_USER_START_ADDR+12);
	printf("first data32 %x\r\n",data32);
	data32 = *(__IO uint32_t *)(FLASH_USER_START_ADDR+16);
	printf("last data32 %x\r\n",data32);
		data32 = *(__IO uint32_t *)(FLASH_USER_START_ADDR+20);
	printf("first data32 %x\r\n",data32);
}
static void storeValue(void)
{
	uint32_t FirstPage = 0, NbOfPages = 0, BankNumber = 0,PageError = 0;
	static FLASH_EraseInitTypeDef EraseInitStruct;
	uint64_t temp;
	/* Unlock the Flash to enable the flash control register access *************/
  HAL_FLASH_Unlock();
	/* Clear OPTVERR bit set on virgin samples */
  __HAL_FLASH_CLEAR_FLAG(FLASH_FLAG_OPTVERR);
	/* Erase the user Flash area
    (area defined by FLASH_USER_START_ADDR and FLASH_USER_END_ADDR) ***********/

  /* Get the 1st page to erase */
  FirstPage = GetPage(FLASH_USER_START_ADDR);

  /* Get the number of pages to erase from 1st page */
  NbOfPages = GetPage(FLASH_USER_END_ADDR) - FirstPage + 1;

  /* Get the bank */
  BankNumber = GetBank(FLASH_USER_START_ADDR);

  /* Fill EraseInit structure*/
  EraseInitStruct.TypeErase   = FLASH_TYPEERASE_PAGES;
  EraseInitStruct.Banks       = BankNumber;
  EraseInitStruct.Page        = FirstPage;
  EraseInitStruct.NbPages     = NbOfPages;

	if (HAL_FLASHEx_Erase(&EraseInitStruct, &PageError) != HAL_OK)
  {
    /*
      Error occurred while page erase.
      User can add here some code to deal with this error.
      PageError will contain the faulty page and then to know the code error on this page,
      user can call function 'HAL_FLASH_GetError()'
    */
		printf("Error occurred while page erase.\r\n");

  }

	/* Program the user Flash area word by word
    (area defined by FLASH_USER_START_ADDR and FLASH_USER_END_ADDR) ***********/

	//temp = DATA_32;
	//temp = temp<<32;
	temp  = 0;
	temp |= (gWIZNETINFO.ip[0] <<24) |(gWIZNETINFO.ip[1] <<16)|(gWIZNETINFO.ip[2] <<8)|gWIZNETINFO.ip[3];
  printf("temp : %x\r\n",(gWIZNETINFO.ip[0] <<24) +(gWIZNETINFO.ip[1] <<16)+(gWIZNETINFO.ip[2] <<8)+gWIZNETINFO.ip[3]);
	temp = DATA_32 | (temp<<32);
    if (HAL_FLASH_Program(FLASH_TYPEPROGRAM_DOUBLEWORD, FLASH_USER_START_ADDR, temp) == HAL_OK)
    {
			printf("Saved!\r\n");
    }
   else
    {
      /* Error occurred while writing data in Flash memory.
         User can add here some code to deal with this error */
			printf("Error occurred while writing data in Flash memory\r\n");

    }

		temp  = 0xFFFFFF01C0A816FC;//sn|fw
		//temp |= (gWIZNETINFO.ip[0] <<24) |(gWIZNETINFO.ip[1] <<16)|(gWIZNETINFO.ip[2] <<8)|gWIZNETINFO.ip[3];
		//printf("temp : %x\r\n",(gWIZNETINFO.ip[0] <<24) +(gWIZNETINFO.ip[1] <<16)+(gWIZNETINFO.ip[2] <<8)+gWIZNETINFO.ip[3]);

		if (HAL_FLASH_Program(FLASH_TYPEPROGRAM_DOUBLEWORD, (FLASH_USER_START_ADDR+8), temp) == HAL_OK)
    {
			printf("Saved!\r\n");
    }
   else
    {
      /* Error occurred while writing data in Flash memory.
         User can add here some code to deal with this error */
			printf("Error occurred while writing data in Flash memory\r\n");

    }

		temp  = 0x0808080801020304;//sn|fw
		//temp |= (gWIZNETINFO.ip[0] <<24) |(gWIZNETINFO.ip[1] <<16)|(gWIZNETINFO.ip[2] <<8)|gWIZNETINFO.ip[3];
		//printf("temp : %x\r\n",(gWIZNETINFO.ip[0] <<24) +(gWIZNETINFO.ip[1] <<16)+(gWIZNETINFO.ip[2] <<8)+gWIZNETINFO.ip[3]);

		if (HAL_FLASH_Program(FLASH_TYPEPROGRAM_DOUBLEWORD, (FLASH_USER_START_ADDR+16), temp) == HAL_OK)
    {
			printf("Saved!\r\n");
    }
   else
    {
      /* Error occurred while writing data in Flash memory.
         User can add here some code to deal with this error */
			printf("Error occurred while writing data in Flash memory\r\n");

    }

	/* Lock the Flash to disable the flash control register access (recommended
     to protect the FLASH memory against possible unwanted operation) *********/
  HAL_FLASH_Lock();
}

/**
  * @brief  Gets the page of a given address
  * @param  Addr: Address of the FLASH Memory
  * @retval The page of a given address
  */
static uint32_t GetPage(uint32_t Addr)
{
  uint32_t page = 0;

  if (Addr < (FLASH_BASE + FLASH_BANK_SIZE))
  {
    /* Bank 1 */
    page = (Addr - FLASH_BASE) / FLASH_PAGE_SIZE;
  }
  else
  {
    /* Bank 2 */
    page = (Addr - (FLASH_BASE + FLASH_BANK_SIZE)) / FLASH_PAGE_SIZE;
  }

  return page;
}

/**
  * @brief  Gets the bank of a given address
  * @param  Addr: Address of the FLASH Memory
  * @retval The bank of a given address
  */
static uint32_t GetBank(uint32_t Addr)
{
  return FLASH_BANK_1;
}
/* USER CODE END 4 */

void Error_Handler(void)
{
}
